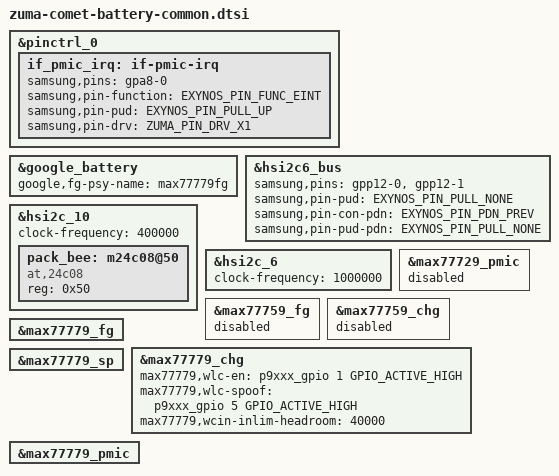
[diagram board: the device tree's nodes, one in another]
// SPDX-License-Identifier: GPL-2.0-only
/*
 * Battery device tree entries for Zuma24
 *
 * Copyright 2022 Google LLC
 *
 */

#include "google-dts-zuma/zuma-battery.dtsi"

&pinctrl_0 {
/* [MAX77729FEWN : INTB] > IF_PMIC_IRQ_L > [XEINT_22 : SC59845XWE] */
	if_pmic_irq: if-pmic-irq {
		samsung,pins = "gpa8-0";
		samsung,pin-function = <EXYNOS_PIN_FUNC_EINT>;
		samsung,pin-pud = <EXYNOS_PIN_PULL_UP>;
		samsung,pin-drv = <ZUMA_PIN_DRV_X1>;
	};

};

&google_battery {
	google,fg-psy-name = "max77779fg";
};

&hsi2c6_bus {
	samsung,pins = "gpp12-0", "gpp12-1";
	samsung,pin-pud = <EXYNOS_PIN_PULL_NONE>;
	samsung,pin-con-pdn = <EXYNOS_PIN_PDN_PREV>;
	samsung,pin-pud-pdn = <EXYNOS_PIN_PULL_NONE>;
};

&hsi2c_10 {
	#address-cells = <1>;
	#size-cells = <0>;
	status = "okay";
	clock-frequency = <400000>;

	pack_bee: m24c08@50 {
		status = "okay";
		compatible = "at,24c08";

		reg = <0x50>;
	};
};

&hsi2c_6 {

	#address-cells = <1>;
	#size-cells = <0>;
	status = "okay";
	clock-frequency = <1000000>;

	#include "google-dts-zuma/zuma-max777xx.dtsi"
};

&max77729_pmic {
	status = "disabled";
};

&max77759_fg {
	status = "disabled";
};

&max77759_chg {
	status = "disabled";
};

&max77779_fg {
	status = "okay";
};

&max77779_chg {
	status = "okay";

	max77779,wlc-en = <&p9xxx_gpio 1 GPIO_ACTIVE_HIGH>;
	max77779,wlc-spoof = <&p9xxx_gpio 5 GPIO_ACTIVE_HIGH>;
	max77779,wcin-inlim-headroom = <40000>;
};

&max77779_sp {
	status = "okay";
};

&max77779_pmic {
	status = "okay";
};
